# apb_timer: IP-XACT component
VLNV pulp-platform.org:peripheral:apb_timer:1.0

## Parameters
REGS_MAX_ADR = 2'd2
APB_ADDR_WIDTH = 12
TIMER_CNT = 2

## Bus interfaces (logical=physical port)
apb_slave: slave amba.com:AMBA3:APB:r1p0_4, memory map TIMER
  PADDR[11:0]=PADDR, PSELx[0:0]=PSEL[0:0], PENABLE[0:0]=PENABLE[0:0], PWRITE[0:0]=PWRITE[0:0], PRDATA=PRDATA, PWDATA=PWDATA, PREADY[0:0]=PREADY[0:0], PSLVERR[0:0]=PSLVERR[0:0]
irq: system pulp-platform.org:interface:irq:1.0
  event[31:28]=irq_o[TIMER_CNT*2-1:0], irq[31:28]=irq_o[TIMER_CNT*2-1:0]

## Ports
in PADDR[APB_ADDR_WIDTH-1:0]
in PSEL
in PENABLE
in PWRITE
out PRDATA[31:0]
in PWDATA[31:0]
out PREADY
out PSLVERR
in HCLK
in HRESETn
out irq_o[(TIMER_CNT * 2) - 1:0] — overflow and cmp interrupt

## Address spaces and blocks
TIMER.timer0_registers: base 'h0, range 'h0C, width 32, register
TIMER.timer1_registers: base 'h10, range 'h0C, width 32, register

## Registers
Registers are 32-bit, access not given, no defined reset value unless marked. A register's access mark holds for its fields unless they carry their own. Offsets are from the block's base; lines under a group give offsets from that group; [hi:lo] are bit positions; {n}, {i} and the like mark numbered series; 'fields as' and 'values as' point back to an identical list; <NAME> marks a mode.

## TIMER.timer0_registers
Base 0x00000000
Same registers: TIMER.timer1_registers 0x00000010
0x00 TIMER
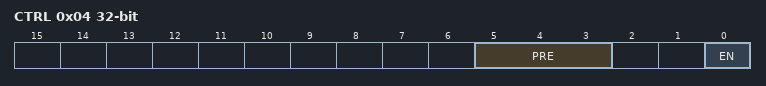
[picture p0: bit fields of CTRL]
0x04 CTRL
  [5:3] PRE, [0] EN
0x08 CMP
